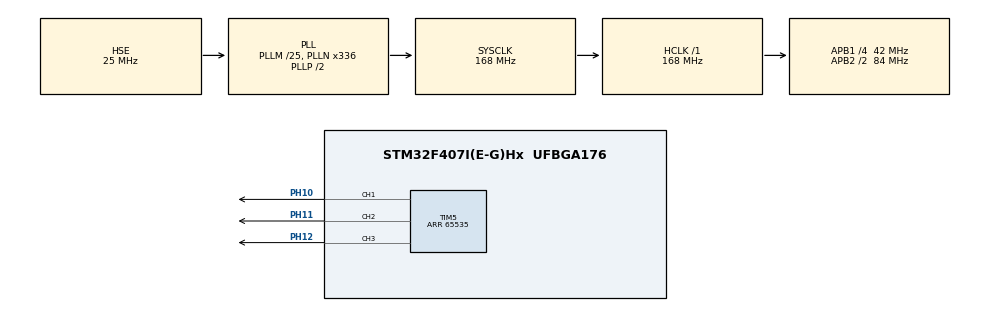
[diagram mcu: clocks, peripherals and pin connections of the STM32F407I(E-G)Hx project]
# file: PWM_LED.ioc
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Mcu.Family=STM32F4
Mcu.Name=STM32F407I(E-G)Hx
Mcu.Package=UFBGA176
NVIC.PriorityGroup=NVIC_PRIORITYGROUP_4
PH0-OSC_IN.Mode=HSE-External-Oscillator
PH0-OSC_IN.Signal=RCC_OSC_IN
PH1-OSC_OUT.Mode=HSE-External-Oscillator
PH1-OSC_OUT.Signal=RCC_OSC_OUT
PH10.Signal=S_TIM5_CH1
PH11.Signal=S_TIM5_CH2
PH12.Signal=S_TIM5_CH3
ProjectManager.HeapSize=0x200
ProjectManager.StackSize=0x400
ProjectManager.TargetToolchain=MDK-ARM V5
RCC.48MHZClocksFreq_Value=84000000
RCC.AHBFreq_Value=168000000
RCC.APB1CLKDivider=RCC_HCLK_DIV4
RCC.APB1Freq_Value=42000000
RCC.APB1TimFreq_Value=84000000
RCC.APB2CLKDivider=RCC_HCLK_DIV2
RCC.APB2Freq_Value=84000000
RCC.APB2TimFreq_Value=168000000
RCC.CortexFreq_Value=168000000
RCC.HCLKFreq_Value=168000000
RCC.HSE_VALUE=25000000
RCC.HSI_VALUE=16000000
RCC.LSE_VALUE=32768
RCC.PLLM=25
RCC.PLLN=336
RCC.PLLSourceVirtual=RCC_PLLSOURCE_HSE
RCC.SYSCLKFreq_VALUE=168000000
RCC.SYSCLKSource=RCC_SYSCLKSOURCE_PLLCLK
RCC.VCOOutputFreq_Value=336000000
SH.S_TIM5_CH1.0=TIM5_CH1,PWM Generation1 CH1
SH.S_TIM5_CH2.0=TIM5_CH2,PWM Generation2 CH2
SH.S_TIM5_CH3.0=TIM5_CH3,PWM Generation3 CH3
TIM5.Channel-PWM\ Generation1\ CH1=TIM_CHANNEL_1
TIM5.Channel-PWM\ Generation2\ CH2=TIM_CHANNEL_2
TIM5.Channel-PWM\ Generation3\ CH3=TIM_CHANNEL_3
TIM5.Period=65535
board=custom

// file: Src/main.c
/* USER CODE BEGIN Header */
/**
  ******************************************************************************
  * @file           : main.c
  * @brief          : Main program body
  ******************************************************************************
  * @attention
  *
  * <h2><center>&copy; Copyright (c) 2020 STMicroelectronics.
  * All rights reserved.</center></h2>
  *
  * This software component is licensed by ST under BSD 3-Clause license,
  * the "License"; You may not use this file except in compliance with the
  * License. You may obtain a copy of the License at:
  *                        opensource.org/licenses/BSD-3-Clause
  *
  ******************************************************************************
  */
/* USER CODE END Header */
#include "main.h"
#include "tim.h"
#include "gpio.h"

/* USER CODE BEGIN PD */
#define COLOR_FLOW_TIME 500  // 每次切换颜色的时间间隔为 500ms
#define COLOR_FLOW_STATE 3  // 共有 3 种颜色形态
/* USER CODE END PD */

void SystemClock_Config(void);
/* USER CODE BEGIN PFP */
void user_led_pwm(uint32_t aRGB);
/* USER CODE END PFP */

int main(void)
{
    /* USER CODE BEGIN 1 */
    // 设置长度为 4 由于便于切换回原状态
    uint32_t color_states[COLOR_FLOW_STATE + 1] = {0xFFFF0000, 0xFF00FF00, 0xFF0000FF, 0xFFFF0000};
    float alpha, red, green, blue;
    float delta_alpha, delta_red, delta_green, delta_blue;
    uint32_t aRGB;
    /* USER CODE END 1 */

    /* MCU Configuration--------------------------------------------------------*/

    /* Reset of all peripherals, Initializes the Flash interface and the Systick. */
    HAL_Init();

    /* Configure the system clock */
    SystemClock_Config();

    /* Initialize all configured peripherals */
    MX_GPIO_Init();
    MX_TIM5_Init();
    /* USER CODE BEGIN 2 */
    HAL_TIM_Base_Start(&htim5);
    HAL_TIM_PWM_Start(&htim5, TIM_CHANNEL_1);
    HAL_TIM_PWM_Start(&htim5, TIM_CHANNEL_2);
    HAL_TIM_PWM_Start(&htim5, TIM_CHANNEL_3);
    /* USER CODE END 2 */

    /* Infinite loop */
    while(1)
    {

        /* USER CODE BEGIN 3 */
        // 循环的计数器
        uint16_t i, j;
        for (i = 0; i < COLOR_FLOW_STATE + 1; i++)
        {
            // 得出目前状态的颜色值
            alpha = (color_states[i] & 0xFF000000) >> 24;
            red = ((color_states[i] & 0x00FF0000) >> 16);
            green = ((color_states[i] & 0x0000FF00) >> 8);
            blue = ((color_states[i] & 0x000000FF) >> 0);
            // 计算出颜色值的在每个 state 转化时的总变化量
            delta_alpha = (float)((color_states[i + 1] & 0xFF000000) >> 24) - (float)((color_states[i] & 0xFF000000) >> 24);
            delta_red = (float)((color_states[i + 1] & 0x00FF0000) >> 16) - (float)((color_states[i] & 0x00FF0000) >> 16);
            delta_green = (float)((color_states[i + 1] & 0x0000FF00) >> 8) - (float)((color_states[i] & 0x0000FF00) >> 8);
            delta_blue = (float)((color_states[i + 1] & 0x000000FF) >> 0) - (float)((color_states[i] & 0x000000FF) >> 0);
            // 计算在 500ms 的每个 毫秒内颜色的变化量
            delta_alpha /= COLOR_FLOW_TIME;
            delta_red /= COLOR_FLOW_TIME;
            delta_green /= COLOR_FLOW_TIME;
            delta_blue /= COLOR_FLOW_TIME;
            // 内循环在 1ms 内微小调节
            for (j = 0; j < COLOR_FLOW_TIME; j++)
            {
                alpha += delta_alpha;
                red += delta_red;
                green += delta_green;
                blue += delta_blue;
                // 混合颜色
                aRGB = (((uint32_t)alpha) << 24) | (((uint32_t)red) << 16) | (((uint32_t)green) << 8) | (((uint32_t)blue) << 0);
                user_led_pwm(aRGB);
                HAL_Delay(1);
            }
        }
    }
    /* USER CODE END 3 */
}

void SystemClock_Config(void)
{
    RCC_OscInitTypeDef RCC_OscInitStruct = {0};
    RCC_ClkInitTypeDef RCC_ClkInitStruct = {0};

    /** Configure the main internal regulator output voltage
    */
    __HAL_RCC_PWR_CLK_ENABLE();
    __HAL_PWR_VOLTAGESCALING_CONFIG(PWR_REGULATOR_VOLTAGE_SCALE1);
    /** Initializes the RCC Oscillators according to the specified parameters
    * in the RCC_OscInitTypeDef structure.
    */
    RCC_OscInitStruct.OscillatorType = RCC_OSCILLATORTYPE_HSE;
    RCC_OscInitStruct.HSEState = RCC_HSE_ON;
    RCC_OscInitStruct.PLL.PLLState = RCC_PLL_ON;
    RCC_OscInitStruct.PLL.PLLSource = RCC_PLLSOURCE_HSE;
    RCC_OscInitStruct.PLL.PLLM = 25;
    RCC_OscInitStruct.PLL.PLLN = 336;
    RCC_OscInitStruct.PLL.PLLP = RCC_PLLP_DIV2;
    RCC_OscInitStruct.PLL.PLLQ = 4;
    if(HAL_RCC_OscConfig(&RCC_OscInitStruct) != HAL_OK)
    {
        Error_Handler();
    }
    /** Initializes the CPU, AHB and APB buses clocks
    */
    RCC_ClkInitStruct.ClockType = RCC_CLOCKTYPE_HCLK | RCC_CLOCKTYPE_SYSCLK
                                  | RCC_CLOCKTYPE_PCLK1 | RCC_CLOCKTYPE_PCLK2;
    RCC_ClkInitStruct.SYSCLKSource = RCC_SYSCLKSOURCE_PLLCLK;
    RCC_ClkInitStruct.AHBCLKDivider = RCC_SYSCLK_DIV1;
    RCC_ClkInitStruct.APB1CLKDivider = RCC_HCLK_DIV4;
    RCC_ClkInitStruct.APB2CLKDivider = RCC_HCLK_DIV2;

    if(HAL_RCC_ClockConfig(&RCC_ClkInitStruct, FLASH_LATENCY_5) != HAL_OK)
    {
        Error_Handler();
    }
}

/* USER CODE BEGIN 4 */
void user_led_pwm(uint32_t aRGB)
{
    // Set the 8 bit vaiables record element
    uint8_t alpha;
    uint8_t red;
    uint8_t green;
    uint8_t blue;
    // Get the value of color PWM
    alpha = (aRGB & 0xFF000000) >> 24;
    red = ((aRGB & 0x00FF0000) >> 16) * alpha;
    green = ((aRGB & 0x0000FF00) >> 8) * alpha;
    blue = ((aRGB & 0x000000FF) >> 0) * alpha;
    // Write the value into TIMx_CCRx
    __HAL_TIM_SetCompare(&htim5, TIM_CHANNEL_1, blue);
    __HAL_TIM_SetCompare(&htim5, TIM_CHANNEL_2, green);
    __HAL_TIM_SetCompare(&htim5, TIM_CHANNEL_3, red);
}
/* USER CODE END 4 */

void Error_Handler(void)
{
}

/************************ (C) COPYRIGHT STMicroelectronics *****END OF FILE****/
